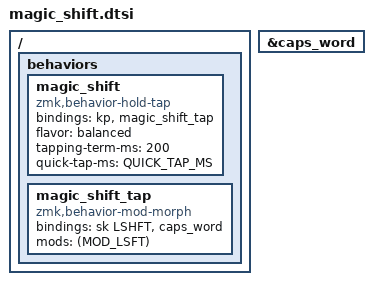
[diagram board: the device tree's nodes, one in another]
#include <dt-bindings/zmk/behaviors.h>
#include <dt-bindings/zmk/keys.h>
#include <zmk-helpers/helper.h>

#define MAGIC_SHIFT &magic_shift LSHFT 0
ZMK_HOLD_TAP(magic_shift, bindings = <&kp>, <&magic_shift_tap>;
             flavor = "balanced"; tapping-term-ms = <200>;
             quick-tap-ms = <QUICK_TAP_MS>;)
ZMK_MOD_MORPH(magic_shift_tap, bindings = <&sk LSHFT>, <&caps_word>;
              mods = <(MOD_LSFT)>;)
&caps_word { // Mods deactivate caps-word, requires PR #1451. [TODO: rebase]
  /delete-property/ ignore-modifiers;
};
